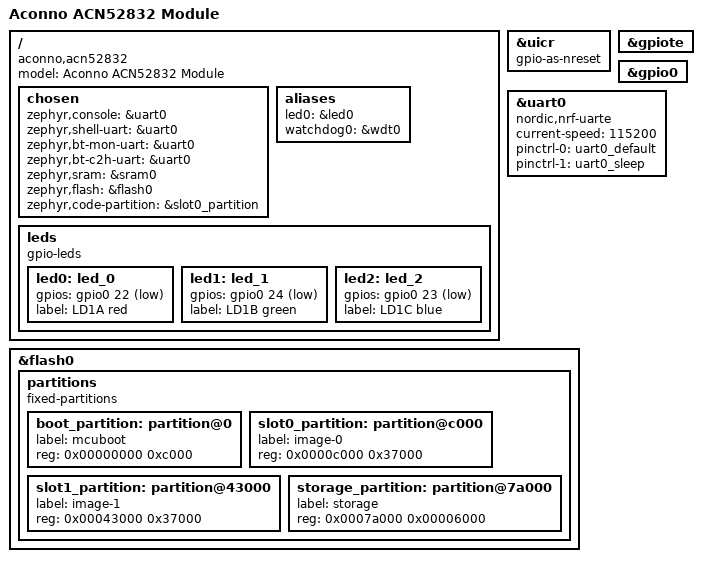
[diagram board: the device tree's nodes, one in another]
/*
 * Copyright (c) 2023 Sven Herrmann
 *
 * SPDX-License-Identifier: Apache-2.0
 */

/dts-v1/;
#include <nordic/nrf52832_qfaa.dtsi>
#include "acn52832-pinctrl.dtsi"

/ {
	model = "Aconno ACN52832 Module";
	compatible = "aconno,acn52832";

	chosen {
		zephyr,console = &uart0;
		zephyr,shell-uart = &uart0;
		zephyr,bt-mon-uart = &uart0;
		zephyr,bt-c2h-uart = &uart0;
		zephyr,sram = &sram0;
		zephyr,flash = &flash0;
		zephyr,code-partition = &slot0_partition;
	};

	/* These aliases are provided for compatibility with samples */
	aliases {
		led0 = &led0;
		watchdog0 = &wdt0;
	};

	leds {
		compatible = "gpio-leds";
		led0: led_0 {
			gpios = <&gpio0 22 GPIO_ACTIVE_LOW>;
			label = "LD1A red";
		};
		led1: led_1 {
			gpios = <&gpio0 24 GPIO_ACTIVE_LOW>;
			label = "LD1B green";
		};
		led2: led_2 {
			gpios = <&gpio0 23 GPIO_ACTIVE_LOW>;
			label = "LD1C blue";
		};
	};
};

&uicr {
	gpio-as-nreset;
};

&gpiote {
	status = "okay";
};

&gpio0 {
	status = "okay";
};

&uart0 {
	compatible = "nordic,nrf-uarte";
	current-speed = <115200>;
	status = "okay";
	pinctrl-0 = <&uart0_default>;
	pinctrl-1 = <&uart0_sleep>;
	pinctrl-names = "default", "sleep";
};

&flash0 {
	partitions {
		compatible = "fixed-partitions";
		#address-cells = <1>;
		#size-cells = <1>;

		boot_partition: partition@0 {
			label = "mcuboot";
			reg = <0x00000000 0xc000>;
		};
		slot0_partition: partition@c000 {
			label = "image-0";
			reg = <0x0000c000 0x37000>;
		};
		slot1_partition: partition@43000 {
			label = "image-1";
			reg = <0x00043000 0x37000>;
		};
		storage_partition: partition@7a000 {
			label = "storage";
			reg = <0x0007a000 0x00006000>;
		};
	};
};
